# STM32F7x5 register map
File version: 1.4
CPU: CM7 r0p0, little endian, no MPU, no FPU, 3 interrupt priority bits
Registers are 32-bit, read-write, reset 0x0 unless marked. A register's access mark holds for its fields unless they carry their own. Offsets are from the block's base; [hi:lo] are bit positions; {n}, {i} and the like mark numbered series; 'fields as' and 'values as' point back to an identical list.

## EXTI — External interrupt/event controller
Base 0x40013C00
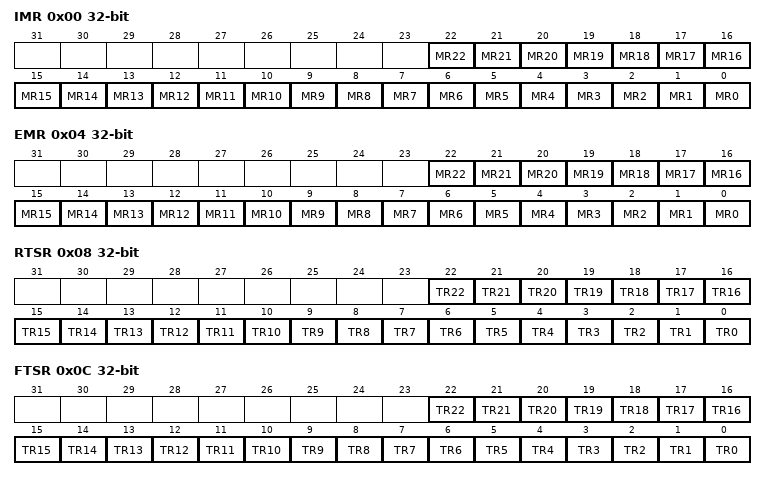
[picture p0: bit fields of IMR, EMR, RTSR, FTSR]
0x00 IMR — Interrupt mask register (EXTI_IMR)
  [n] MR{n} (n=0..22) — Interrupt Mask on line {n}
0x04 EMR — Event mask register (EXTI_EMR)
  [n] MR{n} (n=0..22) — Event Mask on line {n}
0x08 RTSR — Rising Trigger selection register (EXTI_RTSR)
  [n] TR{n} (n=0..22) — Rising trigger event configuration of line {n}
0x0C FTSR — Falling Trigger selection register (EXTI_FTSR)
  [n] TR{n} (n=0..22) — Falling trigger event configuration of line {n}
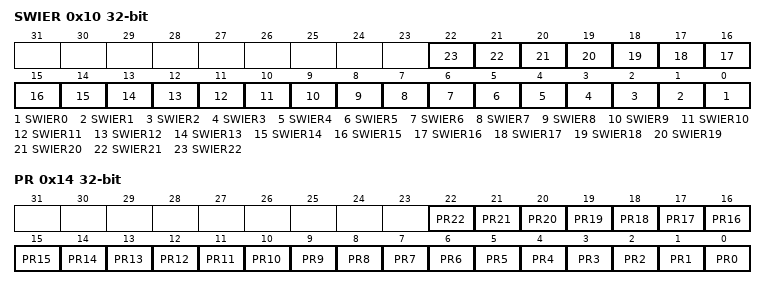
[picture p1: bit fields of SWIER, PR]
0x10 SWIER — Software interrupt event register (EXTI_SWIER)
  [n] SWIER{n} (n=0..22) — Software Interrupt on line {n}
0x14 PR — Pending register (EXTI_PR)
  [n] PR{n} (n=0..22) — Pending bit {n}

## DMA2D — DMA2D controller
Base 0x4002B000
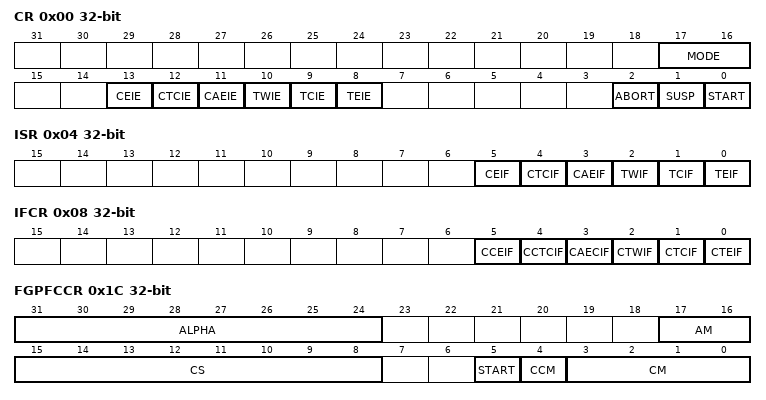
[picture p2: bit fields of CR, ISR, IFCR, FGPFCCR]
0x00 CR — control register
  [17:16] MODE — DMA2D mode
  [13] CEIE — Configuration Error Interrupt Enable
  [12] CTCIE — CLUT transfer complete interrupt enable
  [11] CAEIE — CLUT access error interrupt enable
  [10] TWIE — Transfer watermark interrupt enable
  [9] TCIE — Transfer complete interrupt enable
  [8] TEIE — Transfer error interrupt enable
  [2] ABORT
  [1] SUSP — Suspend
  [0] START
0x04 ISR ro — Interrupt Status Register
  [5] CEIF — Configuration error interrupt flag
  [4] CTCIF — CLUT transfer complete interrupt flag
  [3] CAEIF — CLUT access error interrupt flag
  [2] TWIF — Transfer watermark interrupt flag
  [1] TCIF — Transfer complete interrupt flag
  [0] TEIF — Transfer error interrupt flag
0x08 IFCR — interrupt flag clear register
  [5] CCEIF — Clear configuration error interrupt flag
  [4] CCTCIF — Clear CLUT transfer complete interrupt flag
  [3] CAECIF — Clear CLUT access error interrupt flag
  [2] CTWIF — Clear transfer watermark interrupt flag
  [1] CTCIF — Clear transfer complete interrupt flag
  [0] CTEIF — Clear Transfer error interrupt flag
0x0C FGMAR — foreground memory address register
  [31:0] MA — Memory address
0x10 FGOR — foreground offset register
  [13:0] LO — Line offset
0x14 BGMAR — background memory address register
  [31:0] MA — Memory address
0x18 BGOR — background offset register
  [13:0] LO — Line offset
0x1C FGPFCCR — foreground PFC control register
  [31:24] ALPHA — Alpha value
  [17:16] AM — Alpha mode
  [15:8] CS — CLUT size
  [5] START
  [4] CCM — CLUT color mode
  [3:0] CM — Color mode
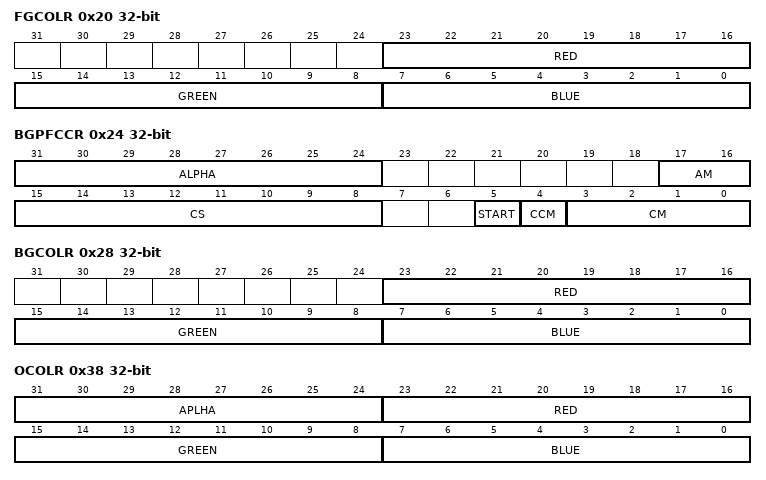
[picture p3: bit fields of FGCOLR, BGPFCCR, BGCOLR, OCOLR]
0x20 FGCOLR — foreground color register
  [23:16] RED — Red Value
  [15:8] GREEN — Green Value
  [7:0] BLUE — Blue Value
0x24 BGPFCCR — background PFC control register
  [31:24] ALPHA — Alpha value
  [17:16] AM — Alpha mode
  [15:8] CS — CLUT size
  [5] START
  [4] CCM — CLUT Color mode
  [3:0] CM — Color mode
0x28 BGCOLR — background color register
  fields as FGCOLR
0x2C FGCMAR — foreground CLUT memory address register
  [31:0] MA — Memory Address
0x30 BGCMAR — background CLUT memory address register
  [31:0] MA — Memory address
0x34 OPFCCR — output PFC control register
  [2:0] CM — Color mode
0x38 OCOLR — output color register
  [31:24] APLHA — Alpha Channel Value
  [23:16] RED — Red Value
  [15:8] GREEN — Green Value
  [7:0] BLUE — Blue Value
0x3C OMAR — output memory address register
  [31:0] MA — Memory Address
0x40 OOR — output offset register
  [13:0] LO — Line Offset
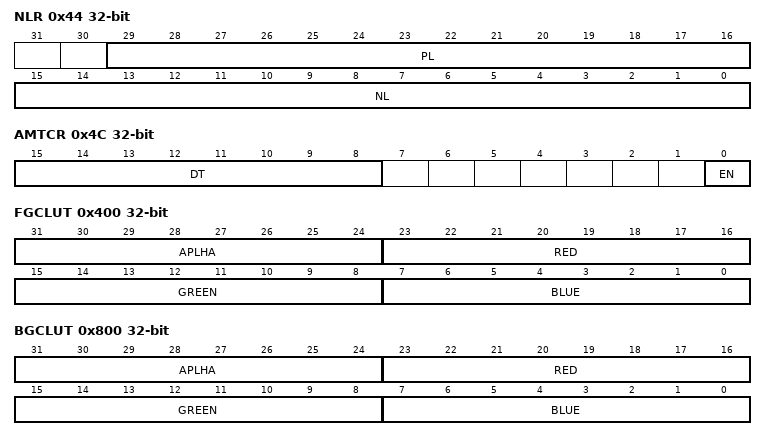
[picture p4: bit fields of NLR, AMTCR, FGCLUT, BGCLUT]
0x44 NLR — number of line register
  [29:16] PL — Pixel per lines
  [15:0] NL — Number of lines
0x48 LWR — line watermark register
  [15:0] LW — Line watermark
0x4C AMTCR — AHB master timer configuration register
  [15:8] DT — Dead Time
  [0] EN — Enable
0x400 FGCLUT
  [31:24] APLHA, [23:16] RED, [15:8] GREEN, [7:0] BLUE
0x800 BGCLUT
  [31:24] APLHA, [23:16] RED, [15:8] GREEN, [7:0] BLUE

## QUADSPI — QuadSPI interface
Base 0xA0001000
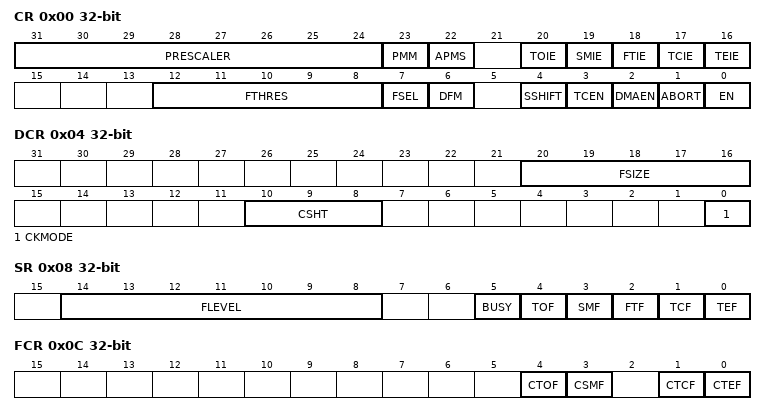
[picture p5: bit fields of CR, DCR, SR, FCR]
0x00 CR — control register
  [31:24] PRESCALER — Clock prescaler
  [23] PMM — Polling match mode
  [22] APMS — Automatic poll mode stop
  [20] TOIE — TimeOut interrupt enable
  [19] SMIE — Status match interrupt enable
  [18] FTIE — FIFO threshold interrupt enable
  [17] TCIE — Transfer complete interrupt enable
  [16] TEIE — Transfer error interrupt enable
  [12:8] FTHRES — IFO threshold level
  [7] FSEL — FLASH memory selection
  [6] DFM — Dual-flash mode
  [4] SSHIFT — Sample shift
  [3] TCEN — Timeout counter enable
  [2] DMAEN — DMA enable
  [1] ABORT — Abort request
  [0] EN — Enable
0x04 DCR — device configuration register
  [20:16] FSIZE — FLASH memory size
  [10:8] CSHT — Chip select high time
  [0] CKMODE — Mode 0 / mode 3
0x08 SR ro — status register
  [14:8] FLEVEL — FIFO level
  [5] BUSY
  [4] TOF — Timeout flag
  [3] SMF — Status match flag
  [2] FTF — FIFO threshold flag
  [1] TCF — Transfer complete flag
  [0] TEF — Transfer error flag
0x0C FCR — flag clear register
  [4] CTOF — Clear timeout flag
  [3] CSMF — Clear status match flag
  [1] CTCF — Clear transfer complete flag
  [0] CTEF — Clear transfer error flag
0x10 DLR — data length register
  [31:0] DL — Data length
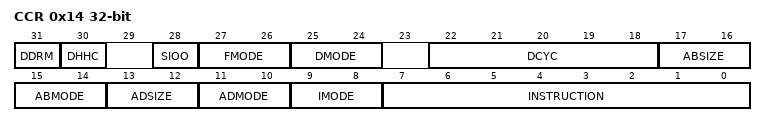
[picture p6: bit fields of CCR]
0x14 CCR — communication configuration register
  [31] DDRM — Double data rate mode
  [30] DHHC — DDR hold half cycle
  [28] SIOO — Send instruction only once mode
  [27:26] FMODE — Functional mode
  [25:24] DMODE — Data mode
  [22:18] DCYC — Number of dummy cycles
  [17:16] ABSIZE — Alternate bytes size
  [15:14] ABMODE — Alternate bytes mode
  [13:12] ADSIZE — Address size
  [11:10] ADMODE — Address mode
  [9:8] IMODE — Instruction mode
  [7:0] INSTRUCTION
0x18 AR — address register
  [31:0] ADDRESS
0x1C ABR
  [31:0] ALTERNATE
0x20 DR — data register
  [31:0] DATA
0x24 PSMKR — polling status mask register
  [31:0] MASK — Status mask
0x28 PSMAR — polling status match register
  [31:0] MATCH — Status match
0x2C PIR — polling interval register
  [15:0] INTERVAL — Polling interval
0x30 LPTR — low-power timeout register
  [15:0] TIMEOUT — Timeout period
